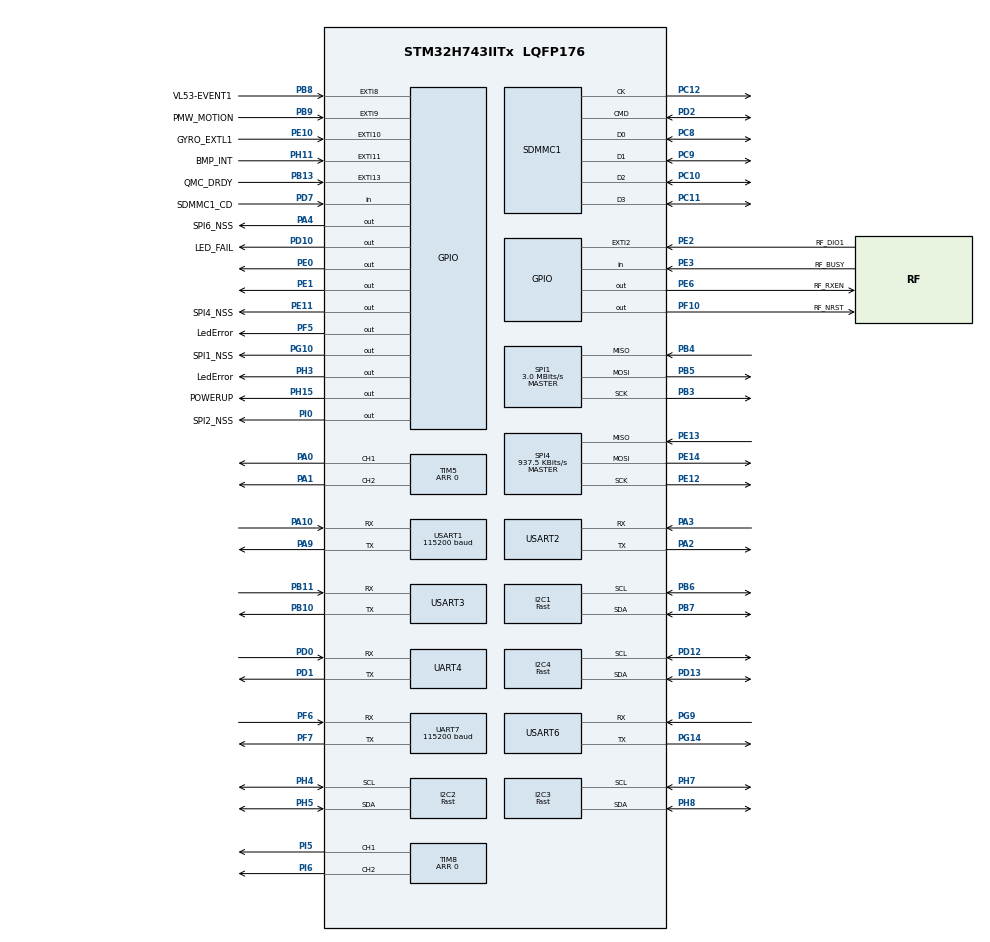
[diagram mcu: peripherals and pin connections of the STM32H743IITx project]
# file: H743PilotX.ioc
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CORTEX_M7.Enable_Spec=__NULL
CORTEX_M7.MPU_Control=__NULL
CORTEX_M7.default_mode_Activation=1
CRC.InputDataFormat=CRC_INPUTDATA_FORMAT_WORDS
Dma.Request0=USART1_TX
Dma.Request1=TIM8_CH1
Dma.Request2=TIM8_CH2
Dma.Request3=TIM5_CH1
Dma.Request4=TIM5_CH2
Dma.Request5=USART1_RX
Dma.Request6=UART7_RX
Dma.Request7=USART2_RX
Dma.TIM5_CH1.3.Direction=DMA_MEMORY_TO_PERIPH
Dma.TIM5_CH1.3.EventEnable=DISABLE
Dma.TIM5_CH1.3.FIFOMode=DMA_FIFOMODE_DISABLE
Dma.TIM5_CH1.3.Instance=DMA2_Stream2
Dma.TIM5_CH1.3.MemDataAlignment=DMA_MDATAALIGN_WORD
Dma.TIM5_CH1.3.MemInc=DMA_MINC_ENABLE
Dma.TIM5_CH1.3.Mode=DMA_NORMAL
Dma.TIM5_CH1.3.PeriphDataAlignment=DMA_PDATAALIGN_WORD
Dma.TIM5_CH1.3.PeriphInc=DMA_PINC_DISABLE
Dma.TIM5_CH1.3.Polarity=HAL_DMAMUX_REQ_GEN_RISING
Dma.TIM5_CH1.3.Priority=DMA_PRIORITY_VERY_HIGH
Dma.TIM5_CH1.3.RequestNumber=1
Dma.TIM5_CH1.3.SignalID=NONE
Dma.TIM5_CH1.3.SyncEnable=DISABLE
Dma.TIM5_CH1.3.SyncPolarity=HAL_DMAMUX_SYNC_NO_EVENT
Dma.TIM5_CH1.3.SyncRequestNumber=1
Dma.TIM5_CH1.3.SyncSignalID=NONE
Dma.TIM5_CH2.4.Direction=DMA_MEMORY_TO_PERIPH
Dma.TIM5_CH2.4.EventEnable=DISABLE
Dma.TIM5_CH2.4.FIFOMode=DMA_FIFOMODE_DISABLE
Dma.TIM5_CH2.4.Instance=DMA2_Stream3
Dma.TIM5_CH2.4.MemDataAlignment=DMA_MDATAALIGN_WORD
Dma.TIM5_CH2.4.MemInc=DMA_MINC_ENABLE
Dma.TIM5_CH2.4.Mode=DMA_NORMAL
Dma.TIM5_CH2.4.PeriphDataAlignment=DMA_PDATAALIGN_WORD
Dma.TIM5_CH2.4.PeriphInc=DMA_PINC_DISABLE
Dma.TIM5_CH2.4.Polarity=HAL_DMAMUX_REQ_GEN_RISING
Dma.TIM5_CH2.4.Priority=DMA_PRIORITY_VERY_HIGH
Dma.TIM5_CH2.4.RequestNumber=1
Dma.TIM5_CH2.4.SignalID=NONE
Dma.TIM5_CH2.4.SyncEnable=DISABLE
Dma.TIM5_CH2.4.SyncPolarity=HAL_DMAMUX_SYNC_NO_EVENT
Dma.TIM5_CH2.4.SyncRequestNumber=1
Dma.TIM5_CH2.4.SyncSignalID=NONE
Dma.TIM8_CH1.1.Direction=DMA_MEMORY_TO_PERIPH
Dma.TIM8_CH1.1.EventEnable=DISABLE
Dma.TIM8_CH1.1.FIFOMode=DMA_FIFOMODE_DISABLE
Dma.TIM8_CH1.1.Instance=DMA2_Stream0
Dma.TIM8_CH1.1.MemDataAlignment=DMA_MDATAALIGN_WORD
Dma.TIM8_CH1.1.MemInc=DMA_MINC_ENABLE
Dma.TIM8_CH1.1.Mode=DMA_NORMAL
Dma.TIM8_CH1.1.PeriphDataAlignment=DMA_PDATAALIGN_WORD
Dma.TIM8_CH1.1.PeriphInc=DMA_PINC_DISABLE
Dma.TIM8_CH1.1.Polarity=HAL_DMAMUX_REQ_GEN_RISING
Dma.TIM8_CH1.1.Priority=DMA_PRIORITY_VERY_HIGH
Dma.TIM8_CH1.1.RequestNumber=1
Dma.TIM8_CH1.1.SignalID=NONE
Dma.TIM8_CH1.1.SyncEnable=DISABLE
Dma.TIM8_CH1.1.SyncPolarity=HAL_DMAMUX_SYNC_NO_EVENT
Dma.TIM8_CH1.1.SyncRequestNumber=1
Dma.TIM8_CH1.1.SyncSignalID=NONE
Dma.TIM8_CH2.2.Direction=DMA_MEMORY_TO_PERIPH
Dma.TIM8_CH2.2.EventEnable=DISABLE
Dma.TIM8_CH2.2.FIFOMode=DMA_FIFOMODE_DISABLE
Dma.TIM8_CH2.2.Instance=DMA2_Stream1
Dma.TIM8_CH2.2.MemDataAlignment=DMA_MDATAALIGN_WORD
Dma.TIM8_CH2.2.MemInc=DMA_MINC_ENABLE
Dma.TIM8_CH2.2.Mode=DMA_NORMAL
Dma.TIM8_CH2.2.PeriphDataAlignment=DMA_PDATAALIGN_WORD
Dma.TIM8_CH2.2.PeriphInc=DMA_PINC_DISABLE
Dma.TIM8_CH2.2.Polarity=HAL_DMAMUX_REQ_GEN_RISING
Dma.TIM8_CH2.2.Priority=DMA_PRIORITY_VERY_HIGH
Dma.TIM8_CH2.2.RequestNumber=1
Dma.TIM8_CH2.2.SignalID=NONE
Dma.TIM8_CH2.2.SyncEnable=DISABLE
Dma.TIM8_CH2.2.SyncPolarity=HAL_DMAMUX_SYNC_NO_EVENT
Dma.TIM8_CH2.2.SyncRequestNumber=1
Dma.TIM8_CH2.2.SyncSignalID=NONE
Dma.UART7_RX.6.Direction=DMA_PERIPH_TO_MEMORY
Dma.UART7_RX.6.EventEnable=DISABLE
Dma.UART7_RX.6.FIFOMode=DMA_FIFOMODE_DISABLE
Dma.UART7_RX.6.Instance=DMA1_Stream0
Dma.UART7_RX.6.MemDataAlignment=DMA_MDATAALIGN_BYTE
Dma.UART7_RX.6.MemInc=DMA_MINC_ENABLE
Dma.UART7_RX.6.Mode=DMA_NORMAL
Dma.UART7_RX.6.PeriphDataAlignment=DMA_PDATAALIGN_BYTE
Dma.UART7_RX.6.PeriphInc=DMA_PINC_DISABLE
Dma.UART7_RX.6.Polarity=HAL_DMAMUX_REQ_GEN_RISING
Dma.UART7_RX.6.Priority=DMA_PRIORITY_MEDIUM
Dma.UART7_RX.6.RequestNumber=1
Dma.UART7_RX.6.SignalID=NONE
Dma.UART7_RX.6.SyncEnable=DISABLE
Dma.UART7_RX.6.SyncPolarity=HAL_DMAMUX_SYNC_NO_EVENT
Dma.UART7_RX.6.SyncRequestNumber=1
Dma.UART7_RX.6.SyncSignalID=NONE
Dma.USART1_RX.5.Direction=DMA_PERIPH_TO_MEMORY
Dma.USART1_RX.5.EventEnable=DISABLE
Dma.USART1_RX.5.FIFOMode=DMA_FIFOMODE_DISABLE
Dma.USART1_RX.5.Instance=DMA1_Stream6
Dma.USART1_RX.5.MemDataAlignment=DMA_MDATAALIGN_BYTE
Dma.USART1_RX.5.MemInc=DMA_MINC_ENABLE
Dma.USART1_RX.5.Mode=DMA_NORMAL
Dma.USART1_RX.5.PeriphDataAlignment=DMA_PDATAALIGN_BYTE
Dma.USART1_RX.5.PeriphInc=DMA_PINC_DISABLE
Dma.USART1_RX.5.Polarity=HAL_DMAMUX_REQ_GEN_RISING
Dma.USART1_RX.5.Priority=DMA_PRIORITY_LOW
Dma.USART1_RX.5.RequestNumber=1
Dma.USART1_RX.5.SignalID=NONE
Dma.USART1_RX.5.SyncEnable=DISABLE
Dma.USART1_RX.5.SyncPolarity=HAL_DMAMUX_SYNC_NO_EVENT
Dma.USART1_RX.5.SyncRequestNumber=1
Dma.USART1_RX.5.SyncSignalID=NONE
Dma.USART1_TX.0.Direction=DMA_MEMORY_TO_PERIPH
Dma.USART1_TX.0.EventEnable=DISABLE
Dma.USART1_TX.0.FIFOMode=DMA_FIFOMODE_DISABLE
Dma.USART1_TX.0.Instance=DMA1_Stream7
Dma.USART1_TX.0.MemDataAlignment=DMA_MDATAALIGN_BYTE
Dma.USART1_TX.0.MemInc=DMA_MINC_ENABLE
Dma.USART1_TX.0.Mode=DMA_NORMAL
Dma.USART1_TX.0.PeriphDataAlignment=DMA_PDATAALIGN_BYTE
Dma.USART1_TX.0.PeriphInc=DMA_PINC_DISABLE
Dma.USART1_TX.0.Polarity=HAL_DMAMUX_REQ_GEN_RISING
Dma.USART1_TX.0.Priority=DMA_PRIORITY_LOW
Dma.USART1_TX.0.RequestNumber=1
Dma.USART1_TX.0.SignalID=NONE
Dma.USART1_TX.0.SyncEnable=DISABLE
Dma.USART1_TX.0.SyncPolarity=HAL_DMAMUX_SYNC_NO_EVENT
Dma.USART1_TX.0.SyncRequestNumber=1
Dma.USART1_TX.0.SyncSignalID=NONE
Dma.USART2_RX.7.Direction=DMA_PERIPH_TO_MEMORY
Dma.USART2_RX.7.EventEnable=DISABLE
Dma.USART2_RX.7.FIFOMode=DMA_FIFOMODE_DISABLE
Dma.USART2_RX.7.Instance=DMA1_Stream1
Dma.USART2_RX.7.MemDataAlignment=DMA_MDATAALIGN_BYTE
Dma.USART2_RX.7.MemInc=DMA_MINC_ENABLE
Dma.USART2_RX.7.Mode=DMA_NORMAL
Dma.USART2_RX.7.PeriphDataAlignment=DMA_PDATAALIGN_BYTE
Dma.USART2_RX.7.PeriphInc=DMA_PINC_DISABLE
Dma.USART2_RX.7.Polarity=HAL_DMAMUX_REQ_GEN_RISING
Dma.USART2_RX.7.Priority=DMA_PRIORITY_LOW
Dma.USART2_RX.7.RequestNumber=1
Dma.USART2_RX.7.SignalID=NONE
Dma.USART2_RX.7.SyncEnable=DISABLE
Dma.USART2_RX.7.SyncPolarity=HAL_DMAMUX_SYNC_NO_EVENT
Dma.USART2_RX.7.SyncRequestNumber=1
Dma.USART2_RX.7.SyncSignalID=NONE
FATFS.BSP.number=1
FATFS.USE_DMA_CODE_SD=1
FATFS._FS_EXFAT=1
FATFS._FS_TINY=0
FATFS._USE_EXPAND=1
FATFS._USE_LFN=3
FATFS0.BSP.STBoard=false
FATFS0.BSP.api=Unknown
FATFS0.BSP.instance=PD7
FATFS0.BSP.ip=GPIO
FATFS0.BSP.mode=Input
FATFS0.BSP.name=Detect_SDIO
FATFS0.BSP.solution=PD7
I2C1.I2C_Speed_Mode=I2C_Fast
I2C1.Timing=0x00B03FDB
I2C2.I2C_Speed_Mode=I2C_Fast
I2C2.Timing=0x00B03FDB
I2C3.I2C_Speed_Mode=I2C_Fast
I2C3.Timing=0x00B03FDB
I2C4.I2C_Speed_Mode=I2C_Fast
I2C4.Timing=0x00B03FDB
Mcu.Family=STM32H7
Mcu.Name=STM32H743IITx
Mcu.Package=LQFP176
NVIC.DMA1_Stream0_IRQn=true\:0\:0\:false\:false\:true\:false\:true\:true
NVIC.DMA1_Stream1_IRQn=true\:0\:0\:false\:false\:true\:false\:true\:true
NVIC.DMA1_Stream6_IRQn=true\:0\:0\:false\:false\:true\:false\:true\:true
NVIC.DMA1_Stream7_IRQn=true\:0\:0\:false\:false\:true\:false\:true\:true
NVIC.DMA2_Stream0_IRQn=true\:0\:0\:false\:false\:true\:false\:true\:true
NVIC.DMA2_Stream1_IRQn=true\:0\:0\:false\:false\:true\:false\:true\:true
NVIC.DMA2_Stream2_IRQn=true\:0\:0\:false\:false\:true\:false\:true\:true
NVIC.DMA2_Stream3_IRQn=true\:0\:0\:false\:false\:true\:false\:true\:true
NVIC.EXTI15_10_IRQn=true\:0\:0\:false\:false\:true\:true\:true\:true
NVIC.EXTI2_IRQn=true\:0\:0\:false\:false\:true\:true\:true\:true
NVIC.EXTI9_5_IRQn=true\:0\:0\:false\:false\:true\:true\:true\:true
NVIC.PriorityGroup=NVIC_PRIORITYGROUP_4
NVIC.SDMMC1_IRQn=true\:0\:0\:false\:false\:true\:true\:true\:true
NVIC.TIM1_UP_IRQn=true\:0\:0\:false\:false\:true\:true\:true\:true
NVIC.TIM2_IRQn=true\:0\:0\:false\:false\:true\:true\:true\:true
NVIC.UART7_IRQn=true\:0\:0\:false\:false\:true\:true\:true\:true
NVIC.USART1_IRQn=true\:0\:0\:false\:false\:true\:true\:true\:true
NVIC.USART2_IRQn=true\:0\:0\:false\:false\:true\:true\:true\:true
PA0.Signal=S_TIM5_CH1
PA1.Signal=S_TIM5_CH2
PA10.Mode=Asynchronous
PA10.Signal=USART1_RX
PA2.Mode=Asynchronous
PA2.Signal=USART2_TX
PA3.GPIO_PuPd=GPIO_PULLUP
PA3.Mode=Asynchronous
PA3.Signal=USART2_RX
PA4.GPIO_Label=SPI6_NSS
PA4.PinState=GPIO_PIN_SET
PA4.Signal=GPIO_Output
PA5.Signal=S_TIM2_CH1_ETR
PA6.Signal=S_TIM3_CH1
PA9.Mode=Asynchronous
PA9.Signal=USART1_TX
PB10.Mode=Asynchronous
PB10.Signal=USART3_TX
PB11.Mode=Asynchronous
PB11.Signal=USART3_RX
PB13.GPIO_Label=QMC_DRDY
PB13.Signal=GPXTI13
PB3\ (JTDO/TRACESWO).Mode=Full_Duplex_Master
PB3\ (JTDO/TRACESWO).Signal=SPI1_SCK
PB4\ (NJTRST).Mode=Full_Duplex_Master
PB4\ (NJTRST).Signal=SPI1_MISO
PB5.Mode=Full_Duplex_Master
PB5.Signal=SPI1_MOSI
PB6.Mode=I2C
PB6.Signal=I2C1_SCL
PB7.Mode=I2C
PB7.Signal=I2C1_SDA
PB8.GPIO_Label=VL53-EVENT1
PB8.Signal=GPXTI8
PB9.GPIO_Label=PMW_MOTION
PB9.Signal=GPXTI9
PC10.Mode=SD_4_bits_Wide_bus
PC10.Signal=SDMMC1_D2
PC11.Mode=SD_4_bits_Wide_bus
PC11.Signal=SDMMC1_D3
PC12.Mode=SD_4_bits_Wide_bus
PC12.Signal=SDMMC1_CK
PC8.Mode=SD_4_bits_Wide_bus
PC8.Signal=SDMMC1_D0
PC9.Mode=SD_4_bits_Wide_bus
PC9.Signal=SDMMC1_D1
PD0.Mode=Asynchronous
PD0.Signal=UART4_RX
PD1.Mode=Asynchronous
PD1.Signal=UART4_TX
PD10.GPIO_Label=LED_FAIL
PD10.Signal=GPIO_Output
PD12.Mode=I2C
PD12.Signal=I2C4_SCL
PD13.Mode=I2C
PD13.Signal=I2C4_SDA
PD2.Mode=SD_4_bits_Wide_bus
PD2.Signal=SDMMC1_CMD
PD7.GPIO_Label=SDMMC1_CD
PD7.Signal=GPIO_Input
PE0.Signal=GPIO_Output
PE1.Signal=GPIO_Output
PE10.GPIO_Label=GYRO_EXTL1
PE10.GPIO_PuPd=GPIO_PULLUP
PE10.Signal=GPXTI10
PE11.GPIO_Label=SPI4_NSS
PE11.GPIO_Speed=GPIO_SPEED_FREQ_HIGH
PE11.PinState=GPIO_PIN_SET
PE11.Signal=GPIO_Output
PE12.Mode=Full_Duplex_Master
PE12.Signal=SPI4_SCK
PE13.Mode=Full_Duplex_Master
PE13.Signal=SPI4_MISO
PE14.Mode=Full_Duplex_Master
PE14.Signal=SPI4_MOSI
PE2.GPIO_Label=RF_DIO1
PE2.Signal=GPXTI2
PE3.GPIO_Label=RF_BUSY
PE3.Signal=GPIO_Input
PE6.GPIO_Label=RF_RXEN
PE6.Signal=GPIO_Output
PF10.GPIO_Label=RF_NRST
PF10.PinState=GPIO_PIN_SET
PF10.Signal=GPIO_Output
PF5.GPIO_Label=LedError
PF5.Signal=GPIO_Output
PF6.Mode=Asynchronous
PF6.Signal=UART7_RX
PF7.Mode=Asynchronous
PF7.Signal=UART7_TX
PG10.GPIO_Label=SPI1_NSS
PG10.PinState=GPIO_PIN_SET
PG10.Signal=GPIO_Output
PG14.Mode=Asynchronous
PG14.Signal=USART6_TX
PG9.Mode=Asynchronous
PG9.Signal=USART6_RX
PH0-OSC_IN\ (PH0).Mode=HSE-External-Oscillator
PH0-OSC_IN\ (PH0).Signal=RCC_OSC_IN
PH1-OSC_OUT\ (PH1).Mode=HSE-External-Oscillator
PH1-OSC_OUT\ (PH1).Signal=RCC_OSC_OUT
PH11.GPIO_Label=BMP_INT
PH11.Signal=GPXTI11
PH15.GPIO_Label=POWERUP
PH15.PinState=GPIO_PIN_SET
PH15.Signal=GPIO_Output
PH3.GPIO_Label=LedError
PH3.Signal=GPIO_Output
PH4.Mode=I2C
PH4.Signal=I2C2_SCL
PH5.Mode=I2C
PH5.Signal=I2C2_SDA
PH7.GPIO_Pu=GPIO_NOPULL
PH7.Mode=I2C
PH7.Signal=I2C3_SCL
PH8.GPIO_Pu=GPIO_NOPULL
PH8.Mode=I2C
PH8.Signal=I2C3_SDA
PI0.GPIO_Label=SPI2_NSS
PI0.Signal=GPIO_Output
PI1.Signal=SPI2_SCK
PI2.Signal=SPI2_MISO
PI3.Signal=SPI2_MOSI
PI5.Signal=S_TIM8_CH1
PI6.Signal=S_TIM8_CH2
ProjectManager.HeapSize=0x1000
ProjectManager.StackSize=0x1600
ProjectManager.TargetToolchain=STM32CubeIDE
RCC.ADCFreq_Value=24187500
RCC.APB1Freq_Value=120000000
RCC.APB2Freq_Value=120000000
RCC.APB3Freq_Value=120000000
RCC.APB4Freq_Value=120000000
RCC.CortexFreq_Value=480000000
RCC.DIVM1=1
RCC.DIVN1=80
RCC.DIVQ1=10
RCC.HCLKFreq_Value=120000000
RCC.HPRE=RCC_HCLK_DIV4
RCC.HSE_VALUE=12000000
RCC.PLL2FRACN=0
RCC.PLL3FRACN=0
RCC.PLLFRACN=0
RCC.PLLSourceVirtual=RCC_PLLSOURCE_HSE
RCC.SYSCLKFreq_VALUE=480000000
RCC.SYSCLKSource=RCC_SYSCLKSOURCE_PLLCLK
RCC.USBFreq_Value=96000000
SDMMC1.ClockDiv=1
SH.S_TIM2_CH1_ETR.0=TIM2_CH1
SH.S_TIM3_CH1.0=TIM3_CH1
SH.S_TIM5_CH1.0=TIM5_CH1,PWM Generation1 CH1
SH.S_TIM5_CH2.0=TIM5_CH2,PWM Generation2 CH2
SH.S_TIM8_CH1.0=TIM8_CH1,PWM Generation1 CH1
SH.S_TIM8_CH2.0=TIM8_CH2,PWM Generation2 CH2
SPI1.BaudRatePrescaler=SPI_BAUDRATEPRESCALER_32
SPI1.CalculateBaudRate=3.0 MBits/s
SPI1.DataSize=SPI_DATASIZE_8BIT
SPI1.Direction=SPI_DIRECTION_2LINES
SPI1.Mode=SPI_MODE_MASTER
SPI1.VirtualType=VM_MASTER
SPI4.BaudRatePrescaler=SPI_BAUDRATEPRESCALER_128
SPI4.CalculateBaudRate=937.5 KBits/s
SPI4.DataSize=SPI_DATASIZE_8BIT
SPI4.Direction=SPI_DIRECTION_2LINES
SPI4.Mode=SPI_MODE_MASTER
SPI4.VirtualType=VM_MASTER
STMicroelectronics.X-CUBE-TOF1.3.4.3.BSP.number=2
STMicroelectronics.X-CUBE-TOF1.3.4.3.TOF_RANGING_MODE=Interrupt
STMicroelectronics.X-CUBE-TOF1.3.4.30.BSP.STBoard=false
STMicroelectronics.X-CUBE-TOF1.3.4.30.BSP.api=Unknown
STMicroelectronics.X-CUBE-TOF1.3.4.30.BSP.condition=SEMBoardOoPartJjRangingJjVL53L5CX
STMicroelectronics.X-CUBE-TOF1.3.4.30.BSP.instance=PE0
STMicroelectronics.X-CUBE-TOF1.3.4.30.BSP.ip=GPIO
STMicroelectronics.X-CUBE-TOF1.3.4.30.BSP.mode=Output
STMicroelectronics.X-CUBE-TOF1.3.4.30.BSP.name=VL53L5CX_LPn
STMicroelectronics.X-CUBE-TOF1.3.4.30.BSP.solution=PE0
STMicroelectronics.X-CUBE-TOF1.3.4.31.BSP.STBoard=false
STMicroelectronics.X-CUBE-TOF1.3.4.31.BSP.api=Unknown
STMicroelectronics.X-CUBE-TOF1.3.4.31.BSP.condition=SEMBoardOoPartJjRangingJjVL53L5CX
STMicroelectronics.X-CUBE-TOF1.3.4.31.BSP.instance=PE1
STMicroelectronics.X-CUBE-TOF1.3.4.31.BSP.ip=GPIO
STMicroelectronics.X-CUBE-TOF1.3.4.31.BSP.mode=Output
STMicroelectronics.X-CUBE-TOF1.3.4.31.BSP.name=VL53L5CX_PWR_EN
STMicroelectronics.X-CUBE-TOF1.3.4.31.BSP.solution=PE1
TIM1.Period=4999
TIM1.Prescaler=119
TIM2.Period=1999
TIM2.Prescaler=119
TIM5.Channel-PWM\ Generation1\ CH1=TIM_CHANNEL_1
TIM5.Channel-PWM\ Generation2\ CH2=TIM_CHANNEL_2
TIM5.Period=0
TIM8.Channel-PWM\ Generation1\ CH1=TIM_CHANNEL_1
TIM8.Channel-PWM\ Generation2\ CH2=TIM_CHANNEL_2
TIM8.Period=0
UART7.BaudRate=115200
USART1.BaudRate=115200
USART1.VirtualMode-Asynchronous=VM_ASYNC
USART2.VirtualMode-Asynchronous=VM_ASYNC
USART3.VirtualMode-Asynchronous=VM_ASYNC
USART6.VirtualMode-Asynchronous=VM_ASYNC
VP_CRC_VS_CRC.Mode=CRC_Activate
VP_FATFS_VS_SDIO.Mode=SDIO
VP_MEMORYMAP_VS_MEMORYMAP.Mode=CurAppReg
VP_TIM1_VS_ClockSourceINT.Mode=Internal
VP_TIM2_VS_ClockSourceINT.Mode=Internal
VP_TIM5_VS_ClockSourceINT.Mode=Internal
VP_TIM8_VS_ClockSourceINT.Mode=Internal
board=custom

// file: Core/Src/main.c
/* USER CODE BEGIN Header */
/**
  ******************************************************************************
  * @file           : main.c
  * @brief          : Main program body
  ******************************************************************************
  * @attention
  *
  * Copyright (c) 2026 STMicroelectronics.
  * All rights reserved.
  *
  * This software is licensed under terms that can be found in the LICENSE file
  * in the root directory of this software component.
  * If no LICENSE file comes with this software, it is provided AS-IS.
  *
  ******************************************************************************
  */
/* USER CODE END Header */
#include "main.h"
#include "crc.h"
#include "dma.h"
#include "fatfs.h"
#include "i2c.h"
#include "sdmmc.h"
#include "spi.h"
#include "tim.h"
#include "usart.h"
#include "gpio.h"

/* USER CODE BEGIN Includes */
#include "cppmain.h"
/* USER CODE END Includes */

void SystemClock_Config(void);

int main(void)
{

  /* MCU Configuration--------------------------------------------------------*/

  /* Reset of all peripherals, Initializes the Flash interface and the Systick. */
  HAL_Init();

  /* Configure the system clock */
  SystemClock_Config();

  /* Initialize all configured peripherals */
  MX_GPIO_Init();
  MX_DMA_Init();
  MX_I2C4_Init();
  MX_CRC_Init();
  MX_SPI1_Init();
  MX_TIM8_Init();
  MX_TIM5_Init();
  MX_TIM1_Init();
  MX_I2C2_Init();
  MX_SPI4_Init();
  MX_USART1_UART_Init();
  MX_I2C3_Init();
  MX_I2C1_Init();
  MX_TIM2_Init();
  MX_SDMMC1_SD_Init();
  MX_FATFS_Init();
  MX_UART4_Init();
  MX_USART2_UART_Init();
  MX_UART7_Init();
  MX_USART3_UART_Init();
  MX_USART6_UART_Init();
  /* USER CODE BEGIN 2 */
  cppmain();
  /* USER CODE END 2 */

  /* Infinite loop */
  while (1)
  {

  }
}

void SystemClock_Config(void)
{
  RCC_OscInitTypeDef RCC_OscInitStruct = {0};
  RCC_ClkInitTypeDef RCC_ClkInitStruct = {0};

  /** Supply configuration update enable
  */
  HAL_PWREx_ConfigSupply(PWR_LDO_SUPPLY);

  /** Configure the main internal regulator output voltage
  */
  __HAL_PWR_VOLTAGESCALING_CONFIG(PWR_REGULATOR_VOLTAGE_SCALE0);

  while(!__HAL_PWR_GET_FLAG(PWR_FLAG_VOSRDY)) {}

  /** Initializes the RCC Oscillators according to the specified parameters
  * in the RCC_OscInitTypeDef structure.
  */
  RCC_OscInitStruct.OscillatorType = RCC_OSCILLATORTYPE_HSE;
  RCC_OscInitStruct.HSEState = RCC_HSE_ON;
  RCC_OscInitStruct.PLL.PLLState = RCC_PLL_ON;
  RCC_OscInitStruct.PLL.PLLSource = RCC_PLLSOURCE_HSE;
  RCC_OscInitStruct.PLL.PLLM = 1;
  RCC_OscInitStruct.PLL.PLLN = 80;
  RCC_OscInitStruct.PLL.PLLP = 2;
  RCC_OscInitStruct.PLL.PLLQ = 10;
  RCC_OscInitStruct.PLL.PLLR = 2;
  RCC_OscInitStruct.PLL.PLLRGE = RCC_PLL1VCIRANGE_3;
  RCC_OscInitStruct.PLL.PLLVCOSEL = RCC_PLL1VCOWIDE;
  RCC_OscInitStruct.PLL.PLLFRACN = 0;
  if (HAL_RCC_OscConfig(&RCC_OscInitStruct) != HAL_OK)
  {
    Error_Handler();
  }

  /** Initializes the CPU, AHB and APB buses clocks
  */
  RCC_ClkInitStruct.ClockType = RCC_CLOCKTYPE_HCLK|RCC_CLOCKTYPE_SYSCLK
                              |RCC_CLOCKTYPE_PCLK1|RCC_CLOCKTYPE_PCLK2
                              |RCC_CLOCKTYPE_D3PCLK1|RCC_CLOCKTYPE_D1PCLK1;
  RCC_ClkInitStruct.SYSCLKSource = RCC_SYSCLKSOURCE_PLLCLK;
  RCC_ClkInitStruct.SYSCLKDivider = RCC_SYSCLK_DIV1;
  RCC_ClkInitStruct.AHBCLKDivider = RCC_HCLK_DIV4;
  RCC_ClkInitStruct.APB3CLKDivider = RCC_APB3_DIV1;
  RCC_ClkInitStruct.APB1CLKDivider = RCC_APB1_DIV1;
  RCC_ClkInitStruct.APB2CLKDivider = RCC_APB2_DIV1;
  RCC_ClkInitStruct.APB4CLKDivider = RCC_APB4_DIV1;

  if (HAL_RCC_ClockConfig(&RCC_ClkInitStruct, FLASH_LATENCY_1) != HAL_OK)
  {
    Error_Handler();
  }
}

void Error_Handler(void)
{
  __disable_irq();
  while (1)
  {
  }
}
